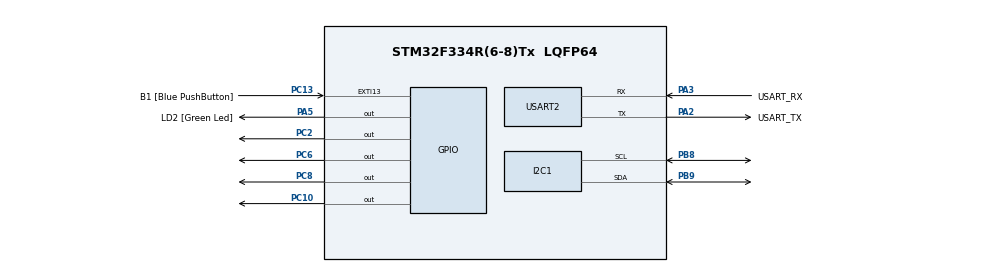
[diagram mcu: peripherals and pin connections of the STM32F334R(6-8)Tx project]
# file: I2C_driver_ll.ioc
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Mcu.Family=STM32F3
Mcu.Name=STM32F334R(6-8)Tx
Mcu.Package=LQFP64
NVIC.PriorityGroup=NVIC_PRIORITYGROUP_0
PA12.Signal=HRTIM1_FLT1
PA13.GPIO_Label=TMS
PA13.Mode=Serial_Wire
PA13.Signal=SYS_JTMS-SWDIO
PA14.GPIO_Label=TCK
PA14.Mode=Serial_Wire
PA14.Signal=SYS_JTCK-SWCLK
PA2.GPIO_Label=USART_TX
PA2.Mode=Asynchronous
PA2.Signal=USART2_TX
PA3.GPIO_Label=USART_RX
PA3.Mode=Asynchronous
PA3.Signal=USART2_RX
PA5.GPIO_Label=LD2 [Green Led]
PA5.Signal=GPIO_Output
PB3.GPIO_Label=SWO
PB3.Signal=SYS_JTDO-TRACESWO
PB8.Mode=I2C
PB8.Signal=I2C1_SCL
PB9.Mode=I2C
PB9.Signal=I2C1_SDA
PC10.Signal=GPIO_Output
PC13.GPIO_Label=B1 [Blue PushButton]
PC13.GPIO_ModeDefaultEXTI=GPIO_MODE_IT_FALLING
PC13.Signal=GPXTI13
PC14\ /\ OSC32_IN.Mode=LSE-External-Oscillator
PC14\ /\ OSC32_IN.Signal=RCC_OSC32_IN
PC15\ /\ OSC32_OUT.GPIO_Label=RCC_OSC32_OUT
PC15\ /\ OSC32_OUT.Mode=LSE-External-Oscillator
PC15\ /\ OSC32_OUT.Signal=RCC_OSC32_OUT
PC2.Signal=GPIO_Output
PC6.Signal=GPIO_Output
PC8.Signal=GPIO_Output
PF0\ /\ OSC_IN.Mode=HSE-External-Clock-Source
PF0\ /\ OSC_IN.Signal=RCC_OSC_IN
PF1\ /\ OSC_OUT.Signal=RCC_OSC_OUT
ProjectManager.HeapSize=0x200
ProjectManager.StackSize=0x400
ProjectManager.TargetToolchain=TrueSTUDIO
RCC.AHBFreq_Value=64000000
RCC.APB1CLKDivider=RCC_HCLK_DIV2
RCC.APB1Freq_Value=32000000
RCC.APB1TimFreq_Value=64000000
RCC.APB2Freq_Value=64000000
RCC.APB2TimFreq_Value=64000000
RCC.CortexFreq_Value=64000000
RCC.FLatency-AdvancedSettings=FLASH_LATENCY_2
RCC.HCLKFreq_Value=64000000
RCC.HSE_VALUE=8000000
RCC.HSI_VALUE=8000000
RCC.PLLMUL=RCC_PLL_MUL16
RCC.SYSCLKFreq_VALUE=64000000
RCC.SYSCLKSourceVirtual=RCC_SYSCLKSOURCE_PLLCLK
USART2.VirtualMode-Asynchronous=VM_ASYNC
board=NUCLEO-F334R8

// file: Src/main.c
/* USER CODE BEGIN Header */
/**
  ******************************************************************************
  * @file           : main.c
  * @brief          : Main program body
  ******************************************************************************
  ** This notice applies to any and all portions of this file
  * that are not between comment pairs USER CODE BEGIN and
  * USER CODE END. Other portions of this file, whether
  * inserted by the user or by software development tools
  * are owned by their respective copyright owners.
  *
  * COPYRIGHT(c) 2019 STMicroelectronics
  *
  * Redistribution and use in source and binary forms, with or without modification,
  * are permitted provided that the following conditions are met:
  *   1. Redistributions of source code must retain the above copyright notice,
  *      this list of conditions and the following disclaimer.
  *   2. Redistributions in binary form must reproduce the above copyright notice,
  *      this list of conditions and the following disclaimer in the documentation
  *      and/or other materials provided with the distribution.
  *   3. Neither the name of STMicroelectronics nor the names of its contributors
  *      may be used to endorse or promote products derived from this software
  *      without specific prior written permission.
  *
  * THIS SOFTWARE IS PROVIDED BY THE COPYRIGHT HOLDERS AND CONTRIBUTORS "AS IS"
  * AND ANY EXPRESS OR IMPLIED WARRANTIES, INCLUDING, BUT NOT LIMITED TO, THE
  * IMPLIED WARRANTIES OF MERCHANTABILITY AND FITNESS FOR A PARTICULAR PURPOSE ARE
  * DISCLAIMED. IN NO EVENT SHALL THE COPYRIGHT HOLDER OR CONTRIBUTORS BE LIABLE
  * FOR ANY DIRECT, INDIRECT, INCIDENTAL, SPECIAL, EXEMPLARY, OR CONSEQUENTIAL
  * DAMAGES (INCLUDING, BUT NOT LIMITED TO, PROCUREMENT OF SUBSTITUTE GOODS OR
  * SERVICES; LOSS OF USE, DATA, OR PROFITS; OR BUSINESS INTERRUPTION) HOWEVER
  * CAUSED AND ON ANY THEORY OF LIABILITY, WHETHER IN CONTRACT, STRICT LIABILITY,
  * OR TORT (INCLUDING NEGLIGENCE OR OTHERWISE) ARISING IN ANY WAY OUT OF THE USE
  * OF THIS SOFTWARE, EVEN IF ADVISED OF THE POSSIBILITY OF SUCH DAMAGE.
  *
  ******************************************************************************
  */
/* USER CODE END Header */

#include "main.h"
#include "i2c.h"
#include "usart.h"
#include "gpio.h"
#include "PCA9685.h"

void SystemClock_Config(void);

int main(void)
{
	  int i = 0;
	  uint8_t addr = 0x80;

  /* MCU Configuration--------------------------------------------------------*/

  /* Reset of all peripherals, Initializes the Flash interface and the Systick. */

  LL_APB2_GRP1_EnableClock(LL_APB2_GRP1_PERIPH_SYSCFG);
  LL_APB1_GRP1_EnableClock(LL_APB1_GRP1_PERIPH_PWR);

  NVIC_SetPriorityGrouping(NVIC_PRIORITYGROUP_0);

  /* System interrupt init*/

  /* Configure the system clock */
  SystemClock_Config();

  /* Initialize all configured peripherals */
  MX_GPIO_Init();
  MX_USART2_UART_Init();
  MX_I2C1_Init();
  /* USER CODE BEGIN 2 */
  pca9685_init(I2C1, addr);
  set_pwm_freq(I2C1,addr,200);
  pca9685_pwm(I2C1, addr, 0, 0, 4095);
  /* USER CODE END 2 */

  /* Infinite loop */
  while (1)
  {
		 for(i=0; i<255; i++)
		 {
			 pca9685_pwm(I2C1, addr, 0, 0, 4095-(16*i));
			 pca9685_pwm(I2C1, addr, 2, 0, (16*i));
			 LL_mDelay(1);
		 }
		 for(i=0; i<255; i++)
		 {
			 pca9685_pwm(I2C1, addr, 0, 0, (16*i));
			 pca9685_pwm(I2C1, addr, 2, 0, 4095-(16*i));
			 LL_mDelay(1);
		 }
  }
}

void SystemClock_Config(void)
{
  LL_FLASH_SetLatency(LL_FLASH_LATENCY_2);

   if(LL_FLASH_GetLatency() != LL_FLASH_LATENCY_2)
  {
  Error_Handler();
  }
  LL_RCC_HSI_Enable();

   /* Wait till HSI is ready */
  while(LL_RCC_HSI_IsReady() != 1)
  {

  }
  LL_RCC_HSI_SetCalibTrimming(16);
  LL_RCC_PLL_ConfigDomain_SYS(LL_RCC_PLLSOURCE_HSI_DIV_2, LL_RCC_PLL_MUL_16);
  LL_RCC_PLL_Enable();

   /* Wait till PLL is ready */
  while(LL_RCC_PLL_IsReady() != 1)
  {

  }
  LL_RCC_SetAHBPrescaler(LL_RCC_SYSCLK_DIV_1);
  LL_RCC_SetAPB1Prescaler(LL_RCC_APB1_DIV_2);
  LL_RCC_SetAPB2Prescaler(LL_RCC_APB1_DIV_1);
  LL_RCC_SetSysClkSource(LL_RCC_SYS_CLKSOURCE_PLL);

   /* Wait till System clock is ready */
  while(LL_RCC_GetSysClkSource() != LL_RCC_SYS_CLKSOURCE_STATUS_PLL)
  {

  }
  LL_Init1msTick(64000000);
  LL_SYSTICK_SetClkSource(LL_SYSTICK_CLKSOURCE_HCLK);
  LL_SetSystemCoreClock(64000000);
  LL_RCC_SetI2CClockSource(LL_RCC_I2C1_CLKSOURCE_HSI);
}

void Error_Handler(void)
{
}

/************************ (C) COPYRIGHT STMicroelectronics *****END OF FILE****/
